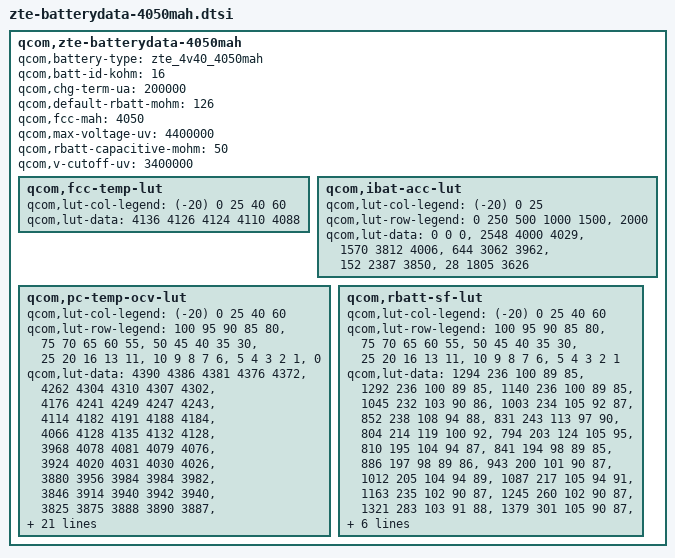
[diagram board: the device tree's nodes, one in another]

qcom,zte-batterydata-4050mah {
	qcom,battery-type = "zte_4v40_4050mah";
	qcom,batt-id-kohm = <16>;
	qcom,chg-term-ua = <200000>;
	qcom,default-rbatt-mohm = <126>;
	qcom,fcc-mah = <4050>;
	qcom,max-voltage-uv = <4400000>;
	qcom,rbatt-capacitive-mohm = <50>;
	qcom,v-cutoff-uv = <3400000>;

	qcom,fcc-temp-lut {
		qcom,lut-col-legend = <(-20) 0 25 40 60>;
		qcom,lut-data = <4136 4126 4124 4110 4088>;
	};

	qcom,ibat-acc-lut {
		qcom,lut-col-legend = <(-20) 0 25>;
		qcom,lut-row-legend = <0 250 500 1000 1500>,
					<2000>;
		qcom,lut-data = <0 0 0>,
				<2548 4000 4029>,
				<1570 3812 4006>,
				<644 3062 3962>,
				<152 2387 3850>,
				<28 1805 3626>;
	};

	qcom,pc-temp-ocv-lut {
		qcom,lut-col-legend = <(-20) 0 25 40 60>;
		qcom,lut-row-legend = <100 95 90 85 80>,
					<75 70 65 60 55>,
					<50 45 40 35 30>,
					<25 20 16 13 11>,
					<10 9 8 7 6>,
					<5 4 3 2 1>,
					<0>;
		qcom,lut-data = <4390 4386 4381 4376 4372>,
				<4262 4304 4310 4307 4302>,
				<4176 4241 4249 4247 4243>,
				<4114 4182 4191 4188 4184>,
				<4066 4128 4135 4132 4128>,
				<3968 4078 4081 4079 4076>,
				<3924 4020 4031 4030 4026>,
				<3880 3956 3984 3984 3982>,
				<3846 3914 3940 3942 3940>,
				<3825 3875 3888 3890 3887>,
				<3810 3844 3852 3853 3852>,
				<3796 3818 3827 3827 3826>,
				<3782 3798 3806 3807 3806>,
				<3768 3784 3790 3790 3788>,
				<3753 3773 3774 3774 3770>,
				<3738 3762 3758 3752 3740>,
				<3723 3745 3739 3730 3718>,
				<3710 3726 3720 3712 3698>,
				<3698 3706 3701 3693 3680>,
				<3688 3694 3689 3682 3671>,
				<3682 3691 3688 3681 3670>,
				<3676 3688 3686 3680 3668>,
				<3667 3685 3684 3678 3666>,
				<3656 3682 3682 3676 3662>,
				<3641 3676 3676 3668 3654>,
				<3620 3660 3654 3647 3626>,
				<3586 3621 3612 3605 3580>,
				<3538 3563 3554 3547 3520>,
				<3461 3484 3473 3468 3440>,
				<3328 3363 3350 3346 3316>,
				<3000 3046 3020 3000 3022>;
	};

	qcom,rbatt-sf-lut {
		qcom,lut-col-legend = <(-20) 0 25 40 60>;
		qcom,lut-row-legend = <100 95 90 85 80>,
					<75 70 65 60 55>,
					<50 45 40 35 30>,
					<25 20 16 13 11>,
					<10 9 8 7 6>,
					<5 4 3 2 1>;
		qcom,lut-data = <1294 236 100 89 85>,
				<1292 236 100 89 85>,
				<1140 236 100 89 85>,
				<1045 232 103 90 86>,
				<1003 234 105 92 87>,
				<852 238 108 94 88>,
				<831 243 113 97 90>,
				<804 214 119 100 92>,
				<794 203 124 105 95>,
				<810 195 104 94 87>,
				<841 194 98 89 85>,
				<886 197 98 89 86>,
				<943 200 101 90 87>,
				<1012 205 104 94 89>,
				<1087 217 105 94 91>,
				<1163 235 102 90 87>,
				<1245 260 102 90 87>,
				<1321 283 103 91 88>,
				<1379 301 105 90 87>,
				<1393 306 102 90 86>,
				<1433 319 103 91 87>,
				<1475 333 106 94 89>,
				<1519 351 109 95 90>,
				<1566 371 113 98 95>,
				<1622 398 116 99 96>,
				<1684 422 113 97 92>,
				<1762 441 114 94 91>,
				<1929 491 118 95 93>,
				<2616 571 123 99 97>,
				<4622 713 141 119 110>;
	};
};
/* TEST_DB_ID=TEST_ID_NOT_SET */
